# Spirit3 register map
File version: 1.0
CPU: CM0+ r0p0, little endian, no MPU, no FPU, 2 interrupt priority bits
Registers are 32-bit, read-write, reset 0x0 unless marked. A register's access mark holds for its fields unless they carry their own. Offsets are from the block's base; [hi:lo] are bit positions; {n}, {i} and the like mark numbered series.

## IWDG — Independent watchdog
Base 0x40003000
0x00 KR wo — Key register
  [15:0] KEY — Key value (write only, read 0x0000)
0x04 PR — Prescaler register
  [2:0] PR — Prescaler divider
0x08 RLR reset 0xFFF — Reload register
  [11:0] RL — Watchdog counter reload value
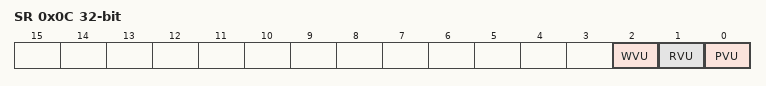
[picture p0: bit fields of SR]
0x0C SR ro — Status register
  [2] WVU — Watchdog counter window prescaler update
  [1] RVU — Watchdog counter reload prescaler update
  [0] PVU — Watchdog prescaler prescaler update
0x10 WINR reset 0xFFF — Window register
  [11:0] WIN — Watchdog counter window value

## LCD — Liquid crystal display controller
Base 0x40007000
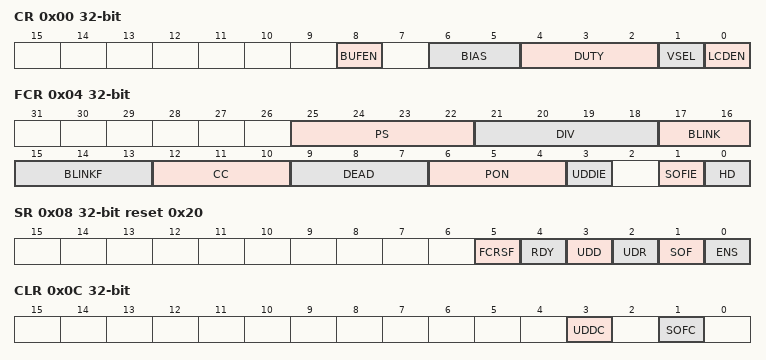
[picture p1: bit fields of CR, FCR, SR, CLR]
0x00 CR — control register
  [8] BUFEN — Voltage output buffer enable
  [6:5] BIAS — Bias selector
  [4:2] DUTY — Duty selection
  [1] VSEL — Voltage source selection
  [0] LCDEN — LCD controller enable
0x04 FCR — frame control register
  [25:22] PS — PS 16-bit prescaler
  [21:18] DIV — DIV clock divider
  [17:16] BLINK — Blink mode selection
  [15:13] BLINKF — Blink frequency selection
  [12:10] CC — Contrast control
  [9:7] DEAD — Dead time duration
  [6:4] PON — Pulse ON duration
  [3] UDDIE — Update display done interrupt enable
  [1] SOFIE — Start of frame interrupt enable
  [0] HD — High drive enable
0x08 SR access per field reset 0x20 — status register
  [5] FCRSF ro — LCD Frame Control Register Synchronization flag
  [4] RDY ro — Ready flag
  [3] UDD ro — Update Display Done
  [2] UDR rw — Update display request
  [1] SOF ro — Start of frame flag
  [0] ENS ro
0x0C CLR wo — clear register
  [3] UDDC — Update display done clear
  [1] SOFC — Start of frame flag clear
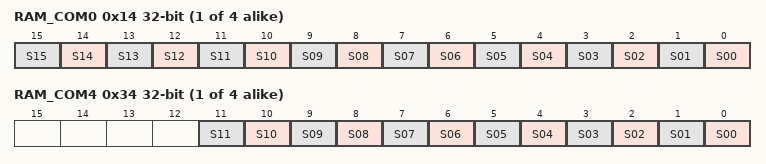
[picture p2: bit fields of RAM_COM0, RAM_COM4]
{0x14+8i} RAM_COM{i} (i=0..3) — display memory
  [n] S{n:02} (n=0..15)
{0x14+8i} RAM_COM{i} (i=4..7) — display memory
  [n] S{n:02} (n=0..11)

## LPUART1 — Universal synchronous asynchronous receiver transmitter
Base 0x41005000
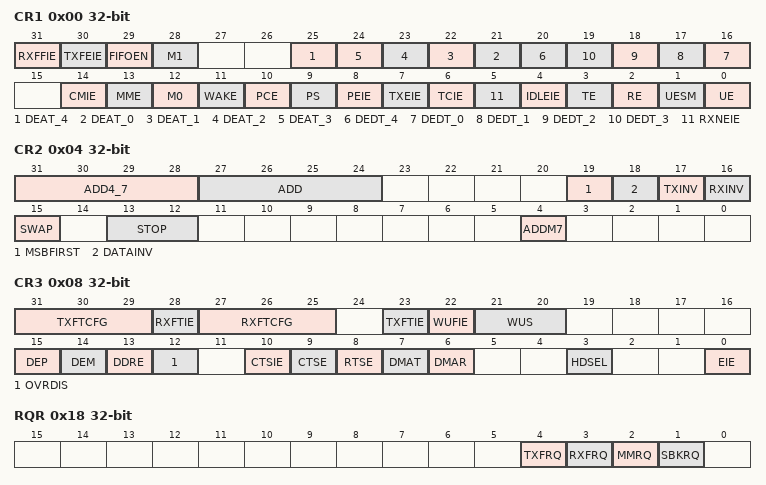
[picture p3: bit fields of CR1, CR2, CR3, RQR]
0x00 CR1 — Control register 1
  [31] RXFFIE
  [30] TXFEIE
  [29] FIFOEN
  [28] M1 — Word length
  [25] DEAT_4 — Driver Enable assertion time
  [n+21] DEAT_{n} (n=0..3)
  [20] DEDT_4 — Driver Enable de-assertion time
  [n+16] DEDT_{n} (n=0..3)
  [14] CMIE — Character match interrupt enable
  [13] MME — Mute mode enable
  [12] M0 — Word length
  [11] WAKE — Receiver wakeup method
  [10] PCE — Parity control enable
  [9] PS — Parity selection
  [8] PEIE — PE interrupt enable
  [7] TXEIE — interrupt enable
  [6] TCIE — Transmission complete interrupt enable
  [5] RXNEIE — RXNE interrupt enable
  [4] IDLEIE — IDLE interrupt enable
  [3] TE — Transmitter enable
  [2] RE — Receiver enable
  [1] UESM — LPUART enable in Stop mode
  [0] UE — USART enable
0x04 CR2 — Control register 2
  [31:28] ADD4_7 — Address of the USART node
  [27:24] ADD — Address of the USART node
  [19] MSBFIRST — Most significant bit first
  [18] DATAINV — Binary data inversion
  [17] TXINV — TX pin active level inversion
  [16] RXINV — RX pin active level inversion
  [15] SWAP — Swap TX/RX pins
  [13:12] STOP — STOP bits
  [4] ADDM7 — 7-bit Address Detection/4-bit address Detection
0x08 CR3 — Control register 3
  [31:29] TXFTCFG — TXFIFO threshold configuration
  [28] RXFTIE
  [27:25] RXFTCFG — Receive FIFO threshold configuration
  [23] TXFTIE — TXFIFO threshold interrupt enable
  [22] WUFIE — Wakeup from Stop mode interrupt enable
  [21:20] WUS — Wakeup from Stop mode interrupt flag selection
  [15] DEP — Driver enable polarity selection
  [14] DEM — Driver enable mode
  [13] DDRE — DMA Disable on reception Error
  [12] OVRDIS — Overrun Disable
  [10] CTSIE — CTs interrupt enable
  [9] CTSE — CTs enable
  [8] RTSE — RTs enable
  [7] DMAT — DMA enable transmitter
  [6] DMAR — DMA enable receiver
  [3] HDSEL — Half-duplex selection
  [0] EIE — Error interrupt enable
0x0C BRR — Baud rate register
  [19:0] BRR
0x18 RQR wo — Request register
  [4] TXFRQ
  [3] RXFRQ — Receive data flush request
  [2] MMRQ — Mute mode request
  [1] SBKRQ — Send break request
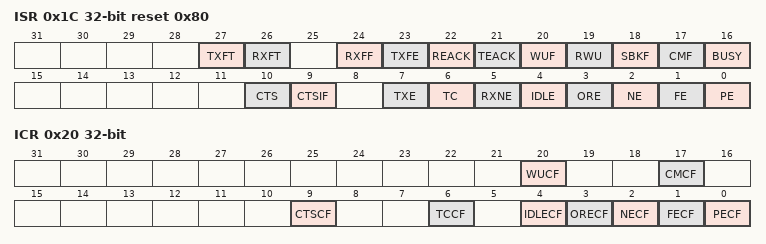
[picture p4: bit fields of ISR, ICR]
0x1C ISR ro reset 0x80 — Interrupt and status register
  [27] TXFT — TXFIFO threshold flag
  [26] RXFT — RXFIFO threshold flag
  [24] RXFF — RXFIFO Full
  [23] TXFE — TXFIFO Empty
  [22] REACK
  [21] TEACK
  [20] WUF — Wakeup from Stop mode flag
  [19] RWU
  [18] SBKF
  [17] CMF
  [16] BUSY
  [10] CTS
  [9] CTSIF
  [7] TXE
  [6] TC
  [5] RXNE
  [4] IDLE
  [3] ORE
  [2] NE — START bit Noise detection flag
  [1] FE
  [0] PE
0x20 ICR — Interrupt flag clear register
  [20] WUCF — Wakeup from Stop mode clear flag
  [17] CMCF — Character match clear flag
  [9] CTSCF — CTs clear flag
  [6] TCCF — Transmission complete clear flag
  [4] IDLECF — Idle line detected clear flag
  [3] ORECF — Overrun error clear flag
  [2] NECF — Noise detected clear flag
  [1] FECF — Framing error clear flag
  [0] PECF — Parity error clear flag
0x24 RDR ro — Receive data register
  [8:0] RDR — Receive data value
0x28 TDR — Transmit data register
  [8:0] TDR — Transmit data value
0x2C PRESC — Prescaler register
  [3:0] PRESCALER — Clock prescaler
